# ESP32 register map
Vendor: ESPRESSIF SYSTEMS (SHANGHAI) CO., LTD.; Series: ESP32 Series; File version: 17
CPU: Xtensa LX6 r0p0, little endian, no MPU, FPU, 0 interrupt priority bits
Address unit: 32 bits
Registers are 32-bit, read-write, reset 0x0 unless marked. A register's access mark holds for its fields unless they carry their own. Offsets are from the block's base; [hi:lo] are bit positions; {n}, {i} and the like mark numbered series.

## SLC — SLC Peripheral
Base 0x3FF58000
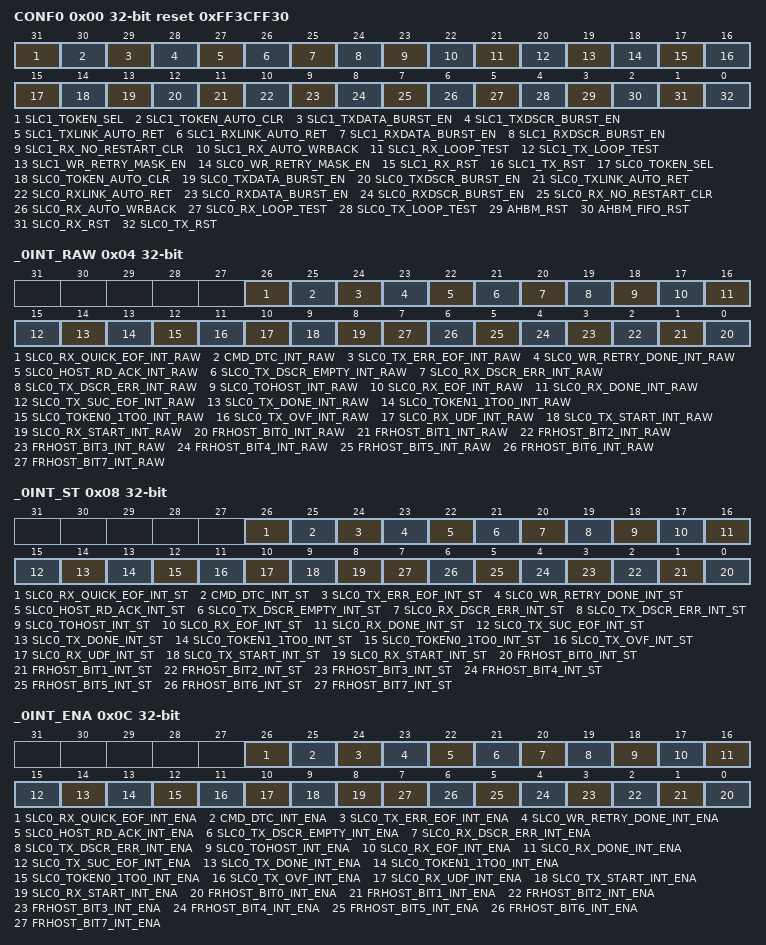
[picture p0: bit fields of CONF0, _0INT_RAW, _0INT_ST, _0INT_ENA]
0x00 CONF0 reset 0xFF3CFF30
  [31] SLC1_TOKEN_SEL, [30] SLC1_TOKEN_AUTO_CLR, [29] SLC1_TXDATA_BURST_EN, [28] SLC1_TXDSCR_BURST_EN, [27] SLC1_TXLINK_AUTO_RET, [26] SLC1_RXLINK_AUTO_RET, [25] SLC1_RXDATA_BURST_EN, [24] SLC1_RXDSCR_BURST_EN, [23] SLC1_RX_NO_RESTART_CLR, [22] SLC1_RX_AUTO_WRBACK, [21] SLC1_RX_LOOP_TEST, [20] SLC1_TX_LOOP_TEST, [19] SLC1_WR_RETRY_MASK_EN, [18] SLC0_WR_RETRY_MASK_EN, [17] SLC1_RX_RST, [16] SLC1_TX_RST, [15] SLC0_TOKEN_SEL, [14] SLC0_TOKEN_AUTO_CLR, [13] SLC0_TXDATA_BURST_EN, [12] SLC0_TXDSCR_BURST_EN, [11] SLC0_TXLINK_AUTO_RET, [10] SLC0_RXLINK_AUTO_RET, [9] SLC0_RXDATA_BURST_EN, [8] SLC0_RXDSCR_BURST_EN, [7] SLC0_RX_NO_RESTART_CLR, [6] SLC0_RX_AUTO_WRBACK, [5] SLC0_RX_LOOP_TEST, [4] SLC0_TX_LOOP_TEST, [3] AHBM_RST, [2] AHBM_FIFO_RST, [1] SLC0_RX_RST, [0] SLC0_TX_RST
0x04 _0INT_RAW ro
  [26] SLC0_RX_QUICK_EOF_INT_RAW, [25] CMD_DTC_INT_RAW, [24] SLC0_TX_ERR_EOF_INT_RAW, [23] SLC0_WR_RETRY_DONE_INT_RAW, [22] SLC0_HOST_RD_ACK_INT_RAW, [21] SLC0_TX_DSCR_EMPTY_INT_RAW, [20] SLC0_RX_DSCR_ERR_INT_RAW, [19] SLC0_TX_DSCR_ERR_INT_RAW, [18] SLC0_TOHOST_INT_RAW, [17] SLC0_RX_EOF_INT_RAW, [16] SLC0_RX_DONE_INT_RAW, [15] SLC0_TX_SUC_EOF_INT_RAW, [14] SLC0_TX_DONE_INT_RAW, [13] SLC0_TOKEN1_1TO0_INT_RAW, [12] SLC0_TOKEN0_1TO0_INT_RAW, [11] SLC0_TX_OVF_INT_RAW, [10] SLC0_RX_UDF_INT_RAW, [9] SLC0_TX_START_INT_RAW, [8] SLC0_RX_START_INT_RAW, [n] FRHOST_BIT{n}_INT_RAW (n=0..7)
0x08 _0INT_ST ro
  [26] SLC0_RX_QUICK_EOF_INT_ST, [25] CMD_DTC_INT_ST, [24] SLC0_TX_ERR_EOF_INT_ST, [23] SLC0_WR_RETRY_DONE_INT_ST, [22] SLC0_HOST_RD_ACK_INT_ST, [21] SLC0_TX_DSCR_EMPTY_INT_ST, [20] SLC0_RX_DSCR_ERR_INT_ST, [19] SLC0_TX_DSCR_ERR_INT_ST, [18] SLC0_TOHOST_INT_ST, [17] SLC0_RX_EOF_INT_ST, [16] SLC0_RX_DONE_INT_ST, [15] SLC0_TX_SUC_EOF_INT_ST, [14] SLC0_TX_DONE_INT_ST, [13] SLC0_TOKEN1_1TO0_INT_ST, [12] SLC0_TOKEN0_1TO0_INT_ST, [11] SLC0_TX_OVF_INT_ST, [10] SLC0_RX_UDF_INT_ST, [9] SLC0_TX_START_INT_ST, [8] SLC0_RX_START_INT_ST, [n] FRHOST_BIT{n}_INT_ST (n=0..7)
0x0C _0INT_ENA
  [26] SLC0_RX_QUICK_EOF_INT_ENA, [25] CMD_DTC_INT_ENA, [24] SLC0_TX_ERR_EOF_INT_ENA, [23] SLC0_WR_RETRY_DONE_INT_ENA, [22] SLC0_HOST_RD_ACK_INT_ENA, [21] SLC0_TX_DSCR_EMPTY_INT_ENA, [20] SLC0_RX_DSCR_ERR_INT_ENA, [19] SLC0_TX_DSCR_ERR_INT_ENA, [18] SLC0_TOHOST_INT_ENA, [17] SLC0_RX_EOF_INT_ENA, [16] SLC0_RX_DONE_INT_ENA, [15] SLC0_TX_SUC_EOF_INT_ENA, [14] SLC0_TX_DONE_INT_ENA, [13] SLC0_TOKEN1_1TO0_INT_ENA, [12] SLC0_TOKEN0_1TO0_INT_ENA, [11] SLC0_TX_OVF_INT_ENA, [10] SLC0_RX_UDF_INT_ENA, [9] SLC0_TX_START_INT_ENA, [8] SLC0_RX_START_INT_ENA, [n] FRHOST_BIT{n}_INT_ENA (n=0..7)
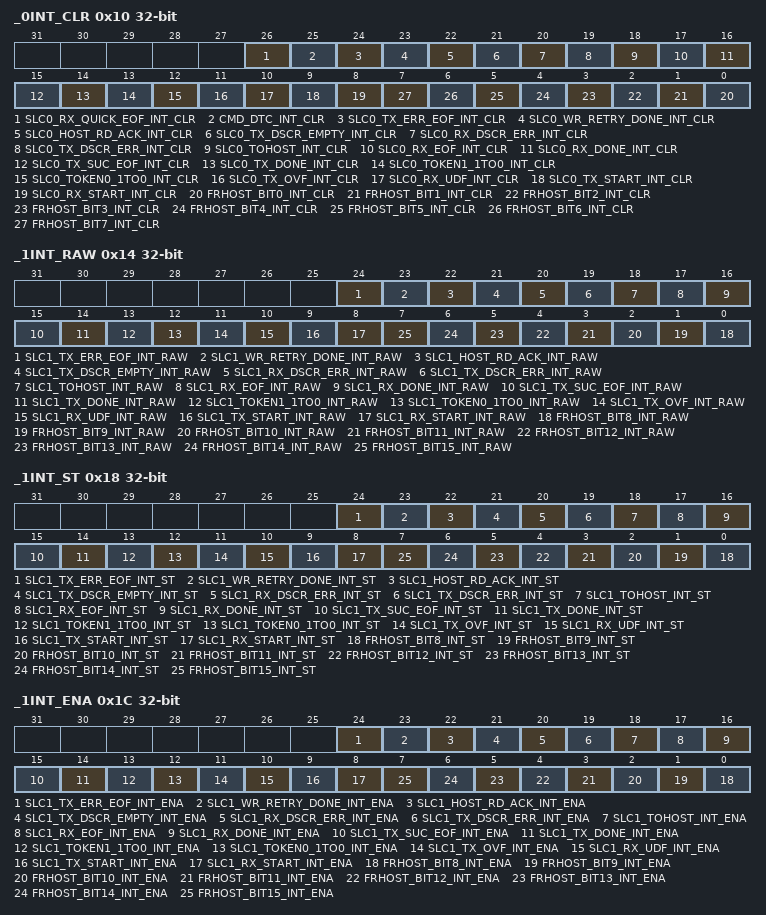
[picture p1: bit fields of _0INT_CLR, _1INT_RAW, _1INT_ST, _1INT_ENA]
0x10 _0INT_CLR wo
  [26] SLC0_RX_QUICK_EOF_INT_CLR, [25] CMD_DTC_INT_CLR, [24] SLC0_TX_ERR_EOF_INT_CLR, [23] SLC0_WR_RETRY_DONE_INT_CLR, [22] SLC0_HOST_RD_ACK_INT_CLR, [21] SLC0_TX_DSCR_EMPTY_INT_CLR, [20] SLC0_RX_DSCR_ERR_INT_CLR, [19] SLC0_TX_DSCR_ERR_INT_CLR, [18] SLC0_TOHOST_INT_CLR, [17] SLC0_RX_EOF_INT_CLR, [16] SLC0_RX_DONE_INT_CLR, [15] SLC0_TX_SUC_EOF_INT_CLR, [14] SLC0_TX_DONE_INT_CLR, [13] SLC0_TOKEN1_1TO0_INT_CLR, [12] SLC0_TOKEN0_1TO0_INT_CLR, [11] SLC0_TX_OVF_INT_CLR, [10] SLC0_RX_UDF_INT_CLR, [9] SLC0_TX_START_INT_CLR, [8] SLC0_RX_START_INT_CLR, [n] FRHOST_BIT{n}_INT_CLR (n=0..7)
0x14 _1INT_RAW ro
  [24] SLC1_TX_ERR_EOF_INT_RAW, [23] SLC1_WR_RETRY_DONE_INT_RAW, [22] SLC1_HOST_RD_ACK_INT_RAW, [21] SLC1_TX_DSCR_EMPTY_INT_RAW, [20] SLC1_RX_DSCR_ERR_INT_RAW, [19] SLC1_TX_DSCR_ERR_INT_RAW, [18] SLC1_TOHOST_INT_RAW, [17] SLC1_RX_EOF_INT_RAW, [16] SLC1_RX_DONE_INT_RAW, [15] SLC1_TX_SUC_EOF_INT_RAW, [14] SLC1_TX_DONE_INT_RAW, [13] SLC1_TOKEN1_1TO0_INT_RAW, [12] SLC1_TOKEN0_1TO0_INT_RAW, [11] SLC1_TX_OVF_INT_RAW, [10] SLC1_RX_UDF_INT_RAW, [9] SLC1_TX_START_INT_RAW, [8] SLC1_RX_START_INT_RAW, [n-8] FRHOST_BIT{n}_INT_RAW (n=8..15)
0x18 _1INT_ST ro
  [24] SLC1_TX_ERR_EOF_INT_ST, [23] SLC1_WR_RETRY_DONE_INT_ST, [22] SLC1_HOST_RD_ACK_INT_ST, [21] SLC1_TX_DSCR_EMPTY_INT_ST, [20] SLC1_RX_DSCR_ERR_INT_ST, [19] SLC1_TX_DSCR_ERR_INT_ST, [18] SLC1_TOHOST_INT_ST, [17] SLC1_RX_EOF_INT_ST, [16] SLC1_RX_DONE_INT_ST, [15] SLC1_TX_SUC_EOF_INT_ST, [14] SLC1_TX_DONE_INT_ST, [13] SLC1_TOKEN1_1TO0_INT_ST, [12] SLC1_TOKEN0_1TO0_INT_ST, [11] SLC1_TX_OVF_INT_ST, [10] SLC1_RX_UDF_INT_ST, [9] SLC1_TX_START_INT_ST, [8] SLC1_RX_START_INT_ST, [n-8] FRHOST_BIT{n}_INT_ST (n=8..15)
0x1C _1INT_ENA
  [24] SLC1_TX_ERR_EOF_INT_ENA, [23] SLC1_WR_RETRY_DONE_INT_ENA, [22] SLC1_HOST_RD_ACK_INT_ENA, [21] SLC1_TX_DSCR_EMPTY_INT_ENA, [20] SLC1_RX_DSCR_ERR_INT_ENA, [19] SLC1_TX_DSCR_ERR_INT_ENA, [18] SLC1_TOHOST_INT_ENA, [17] SLC1_RX_EOF_INT_ENA, [16] SLC1_RX_DONE_INT_ENA, [15] SLC1_TX_SUC_EOF_INT_ENA, [14] SLC1_TX_DONE_INT_ENA, [13] SLC1_TOKEN1_1TO0_INT_ENA, [12] SLC1_TOKEN0_1TO0_INT_ENA, [11] SLC1_TX_OVF_INT_ENA, [10] SLC1_RX_UDF_INT_ENA, [9] SLC1_TX_START_INT_ENA, [8] SLC1_RX_START_INT_ENA, [n-8] FRHOST_BIT{n}_INT_ENA (n=8..15)
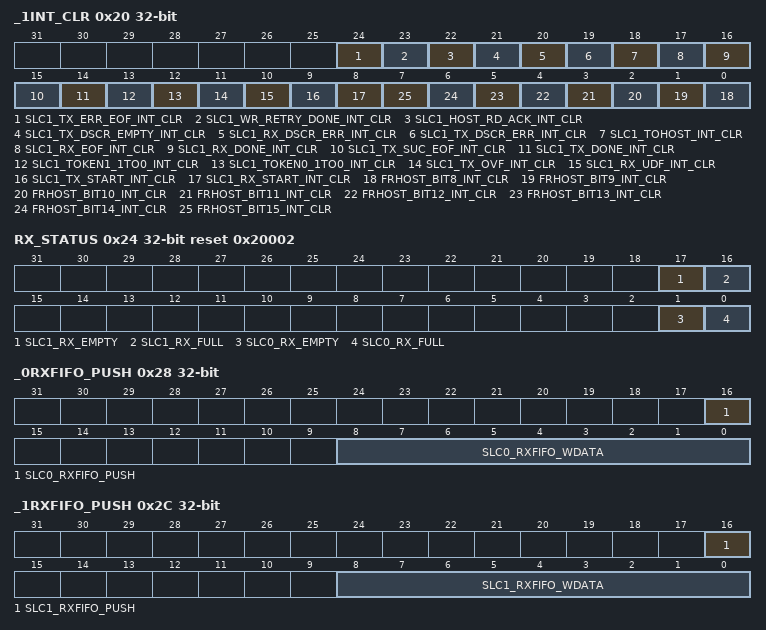
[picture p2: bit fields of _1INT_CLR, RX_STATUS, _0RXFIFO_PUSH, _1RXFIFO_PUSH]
0x20 _1INT_CLR wo
  [24] SLC1_TX_ERR_EOF_INT_CLR, [23] SLC1_WR_RETRY_DONE_INT_CLR, [22] SLC1_HOST_RD_ACK_INT_CLR, [21] SLC1_TX_DSCR_EMPTY_INT_CLR, [20] SLC1_RX_DSCR_ERR_INT_CLR, [19] SLC1_TX_DSCR_ERR_INT_CLR, [18] SLC1_TOHOST_INT_CLR, [17] SLC1_RX_EOF_INT_CLR, [16] SLC1_RX_DONE_INT_CLR, [15] SLC1_TX_SUC_EOF_INT_CLR, [14] SLC1_TX_DONE_INT_CLR, [13] SLC1_TOKEN1_1TO0_INT_CLR, [12] SLC1_TOKEN0_1TO0_INT_CLR, [11] SLC1_TX_OVF_INT_CLR, [10] SLC1_RX_UDF_INT_CLR, [9] SLC1_TX_START_INT_CLR, [8] SLC1_RX_START_INT_CLR, [n-8] FRHOST_BIT{n}_INT_CLR (n=8..15)
0x24 RX_STATUS ro reset 0x20002
  [17] SLC1_RX_EMPTY, [16] SLC1_RX_FULL, [1] SLC0_RX_EMPTY, [0] SLC0_RX_FULL
0x28 _0RXFIFO_PUSH
  [16] SLC0_RXFIFO_PUSH, [8:0] SLC0_RXFIFO_WDATA
0x2C _1RXFIFO_PUSH
  [16] SLC1_RXFIFO_PUSH, [8:0] SLC1_RXFIFO_WDATA
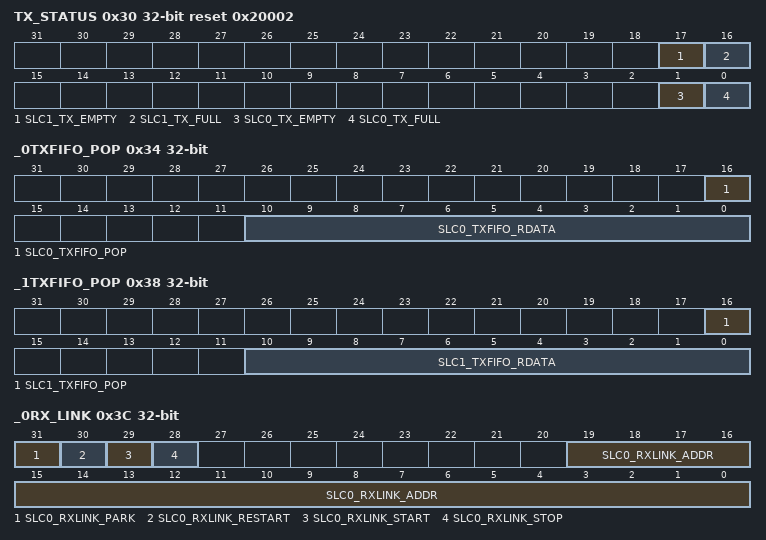
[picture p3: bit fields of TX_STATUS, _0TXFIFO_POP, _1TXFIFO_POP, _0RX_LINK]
0x30 TX_STATUS ro reset 0x20002
  [17] SLC1_TX_EMPTY, [16] SLC1_TX_FULL, [1] SLC0_TX_EMPTY, [0] SLC0_TX_FULL
0x34 _0TXFIFO_POP access per field
  [16] SLC0_TXFIFO_POP rw, [10:0] SLC0_TXFIFO_RDATA ro
0x38 _1TXFIFO_POP access per field
  [16] SLC1_TXFIFO_POP rw, [10:0] SLC1_TXFIFO_RDATA ro
0x3C _0RX_LINK access per field
  [31] SLC0_RXLINK_PARK ro, [30] SLC0_RXLINK_RESTART rw, [29] SLC0_RXLINK_START rw, [28] SLC0_RXLINK_STOP rw, [19:0] SLC0_RXLINK_ADDR rw
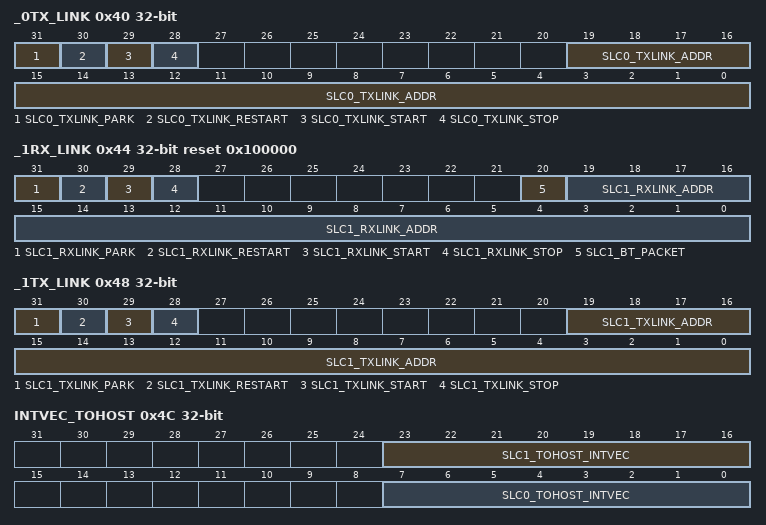
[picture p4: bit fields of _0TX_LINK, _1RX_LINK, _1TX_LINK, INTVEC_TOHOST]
0x40 _0TX_LINK access per field
  [31] SLC0_TXLINK_PARK ro, [30] SLC0_TXLINK_RESTART rw, [29] SLC0_TXLINK_START rw, [28] SLC0_TXLINK_STOP rw, [19:0] SLC0_TXLINK_ADDR rw
0x44 _1RX_LINK access per field reset 0x100000
  [31] SLC1_RXLINK_PARK ro, [30] SLC1_RXLINK_RESTART rw, [29] SLC1_RXLINK_START rw, [28] SLC1_RXLINK_STOP rw, [20] SLC1_BT_PACKET rw, [19:0] SLC1_RXLINK_ADDR rw
0x48 _1TX_LINK access per field
  [31] SLC1_TXLINK_PARK ro, [30] SLC1_TXLINK_RESTART rw, [29] SLC1_TXLINK_START rw, [28] SLC1_TXLINK_STOP rw, [19:0] SLC1_TXLINK_ADDR rw
0x4C INTVEC_TOHOST wo
  [23:16] SLC1_TOHOST_INTVEC, [7:0] SLC0_TOHOST_INTVEC
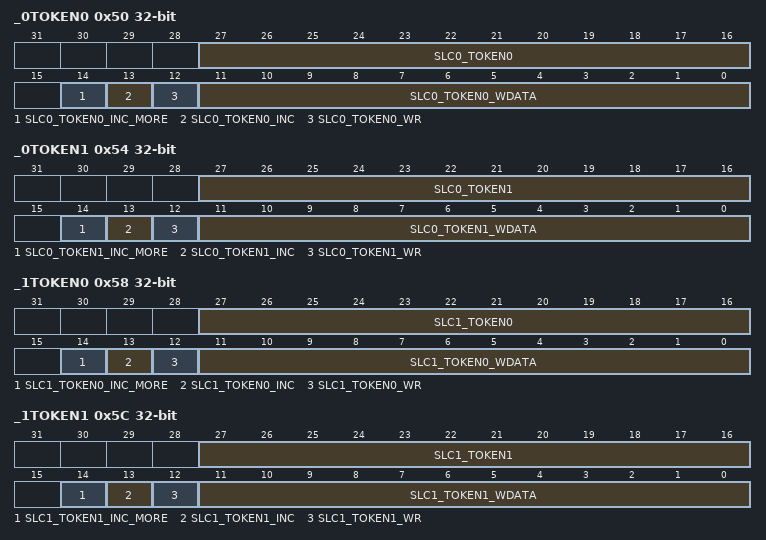
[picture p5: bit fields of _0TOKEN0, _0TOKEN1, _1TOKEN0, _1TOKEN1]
0x50 _0TOKEN0 access per field
  [27:16] SLC0_TOKEN0 ro, [14] SLC0_TOKEN0_INC_MORE wo, [13] SLC0_TOKEN0_INC wo, [12] SLC0_TOKEN0_WR wo, [11:0] SLC0_TOKEN0_WDATA wo
0x54 _0TOKEN1 access per field
  [27:16] SLC0_TOKEN1 ro, [14] SLC0_TOKEN1_INC_MORE wo, [13] SLC0_TOKEN1_INC wo, [12] SLC0_TOKEN1_WR wo, [11:0] SLC0_TOKEN1_WDATA wo
0x58 _1TOKEN0 access per field
  [27:16] SLC1_TOKEN0 ro, [14] SLC1_TOKEN0_INC_MORE wo, [13] SLC1_TOKEN0_INC wo, [12] SLC1_TOKEN0_WR wo, [11:0] SLC1_TOKEN0_WDATA wo
0x5C _1TOKEN1 access per field
  [27:16] SLC1_TOKEN1 ro, [14] SLC1_TOKEN1_INC_MORE wo, [13] SLC1_TOKEN1_INC wo, [12] SLC1_TOKEN1_WR wo, [11:0] SLC1_TOKEN1_WDATA wo
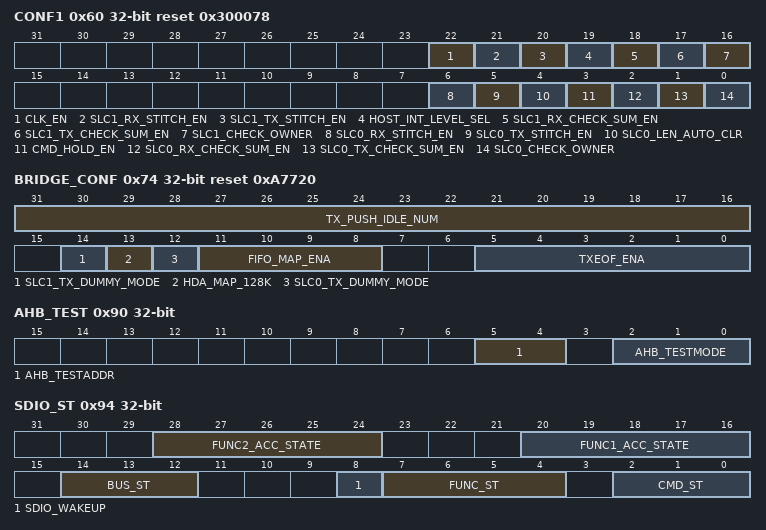
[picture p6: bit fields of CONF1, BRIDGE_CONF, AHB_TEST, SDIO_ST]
0x60 CONF1 reset 0x300078
  [22] CLK_EN, [21] SLC1_RX_STITCH_EN, [20] SLC1_TX_STITCH_EN, [19] HOST_INT_LEVEL_SEL, [18] SLC1_RX_CHECK_SUM_EN, [17] SLC1_TX_CHECK_SUM_EN, [16] SLC1_CHECK_OWNER, [6] SLC0_RX_STITCH_EN, [5] SLC0_TX_STITCH_EN, [4] SLC0_LEN_AUTO_CLR, [3] CMD_HOLD_EN, [2] SLC0_RX_CHECK_SUM_EN, [1] SLC0_TX_CHECK_SUM_EN, [0] SLC0_CHECK_OWNER
0x64 _0_STATE0 ro
  [31:0] SLC0_STATE0
0x68 _0_STATE1 ro
  [31:0] SLC0_STATE1
0x6C _1_STATE0 ro
  [31:0] SLC1_STATE0
0x70 _1_STATE1 ro
  [31:0] SLC1_STATE1
0x74 BRIDGE_CONF reset 0xA7720
  [31:16] TX_PUSH_IDLE_NUM, [14] SLC1_TX_DUMMY_MODE, [13] HDA_MAP_128K, [12] SLC0_TX_DUMMY_MODE, [11:8] FIFO_MAP_ENA, [5:0] TXEOF_ENA
0x78 _0_TO_EOF_DES_ADDR ro
  [31:0] SLC0_TO_EOF_DES_ADDR
0x7C _0_TX_EOF_DES_ADDR ro
  [31:0] SLC0_TX_SUC_EOF_DES_ADDR
0x80 _0_TO_EOF_BFR_DES_ADDR ro
  [31:0] SLC0_TO_EOF_BFR_DES_ADDR
0x84 _1_TO_EOF_DES_ADDR ro
  [31:0] SLC1_TO_EOF_DES_ADDR
0x88 _1_TX_EOF_DES_ADDR ro
  [31:0] SLC1_TX_SUC_EOF_DES_ADDR
0x8C _1_TO_EOF_BFR_DES_ADDR ro
  [31:0] SLC1_TO_EOF_BFR_DES_ADDR
0x90 AHB_TEST
  [5:4] AHB_TESTADDR, [2:0] AHB_TESTMODE
0x94 SDIO_ST ro
  [28:24] FUNC2_ACC_STATE, [20:16] FUNC1_ACC_STATE, [14:12] BUS_ST, [8] SDIO_WAKEUP, [7:4] FUNC_ST, [2:0] CMD_ST
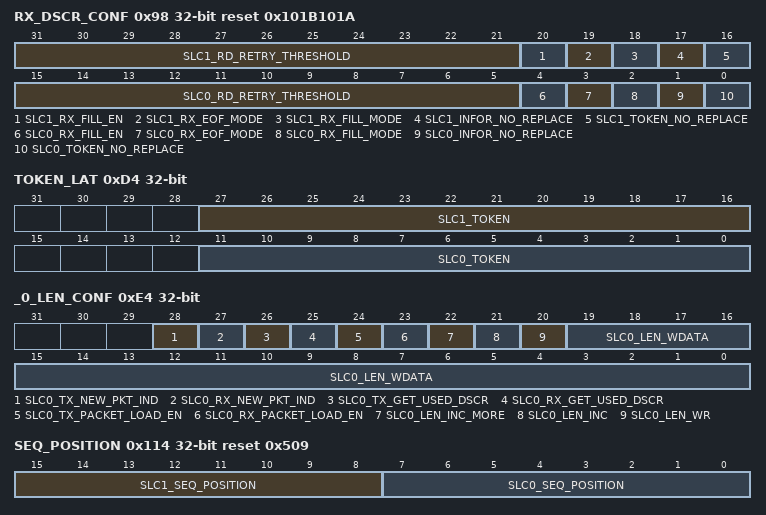
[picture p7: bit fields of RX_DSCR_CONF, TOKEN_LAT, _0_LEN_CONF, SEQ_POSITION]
0x98 RX_DSCR_CONF reset 0x101B101A
  [31:21] SLC1_RD_RETRY_THRESHOLD, [20] SLC1_RX_FILL_EN, [19] SLC1_RX_EOF_MODE, [18] SLC1_RX_FILL_MODE, [17] SLC1_INFOR_NO_REPLACE, [16] SLC1_TOKEN_NO_REPLACE, [15:5] SLC0_RD_RETRY_THRESHOLD, [4] SLC0_RX_FILL_EN, [3] SLC0_RX_EOF_MODE, [2] SLC0_RX_FILL_MODE, [1] SLC0_INFOR_NO_REPLACE, [0] SLC0_TOKEN_NO_REPLACE
0x9C _0_TXLINK_DSCR ro
  [31:0] SLC0_TXLINK_DSCR
0xA0 _0_TXLINK_DSCR_BF0 ro
  [31:0] SLC0_TXLINK_DSCR_BF0
0xA4 _0_TXLINK_DSCR_BF1 ro
  [31:0] SLC0_TXLINK_DSCR_BF1
0xA8 _0_RXLINK_DSCR ro
  [31:0] SLC0_RXLINK_DSCR
0xAC _0_RXLINK_DSCR_BF0 ro
  [31:0] SLC0_RXLINK_DSCR_BF0
0xB0 _0_RXLINK_DSCR_BF1 ro
  [31:0] SLC0_RXLINK_DSCR_BF1
0xB4 _1_TXLINK_DSCR ro
  [31:0] SLC1_TXLINK_DSCR
0xB8 _1_TXLINK_DSCR_BF0 ro
  [31:0] SLC1_TXLINK_DSCR_BF0
0xBC _1_TXLINK_DSCR_BF1 ro
  [31:0] SLC1_TXLINK_DSCR_BF1
0xC0 _1_RXLINK_DSCR ro
  [31:0] SLC1_RXLINK_DSCR
0xC4 _1_RXLINK_DSCR_BF0 ro
  [31:0] SLC1_RXLINK_DSCR_BF0
0xC8 _1_RXLINK_DSCR_BF1 ro
  [31:0] SLC1_RXLINK_DSCR_BF1
0xCC _0_TX_ERREOF_DES_ADDR ro
  [31:0] SLC0_TX_ERR_EOF_DES_ADDR
0xD0 _1_TX_ERREOF_DES_ADDR ro
  [31:0] SLC1_TX_ERR_EOF_DES_ADDR
0xD4 TOKEN_LAT ro
  [27:16] SLC1_TOKEN, [11:0] SLC0_TOKEN
0xD8 TX_DSCR_CONF reset 0x80
  [10:0] WR_RETRY_THRESHOLD
0xDC CMD_INFOR0 ro
  [31:0] CMD_CONTENT0
0xE0 CMD_INFOR1 ro
  [31:0] CMD_CONTENT1
0xE4 _0_LEN_CONF access per field
  [28] SLC0_TX_NEW_PKT_IND ro, [27] SLC0_RX_NEW_PKT_IND ro, [26] SLC0_TX_GET_USED_DSCR wo, [25] SLC0_RX_GET_USED_DSCR wo, [24] SLC0_TX_PACKET_LOAD_EN rw, [23] SLC0_RX_PACKET_LOAD_EN rw, [22] SLC0_LEN_INC_MORE wo, [21] SLC0_LEN_INC wo, [20] SLC0_LEN_WR wo, [19:0] SLC0_LEN_WDATA wo
0xE8 _0_LENGTH ro
  [19:0] SLC0_LEN
0xEC _0_TXPKT_H_DSCR
  [31:0] SLC0_TX_PKT_H_DSCR_ADDR
0xF0 _0_TXPKT_E_DSCR
  [31:0] SLC0_TX_PKT_E_DSCR_ADDR
0xF4 _0_RXPKT_H_DSCR
  [31:0] SLC0_RX_PKT_H_DSCR_ADDR
0xF8 _0_RXPKT_E_DSCR
  [31:0] SLC0_RX_PKT_E_DSCR_ADDR
0xFC _0_TXPKTU_H_DSCR ro
  [31:0] SLC0_TX_PKT_START_DSCR_ADDR
0x100 _0_TXPKTU_E_DSCR ro
  [31:0] SLC0_TX_PKT_END_DSCR_ADDR
0x104 _0_RXPKTU_H_DSCR ro
  [31:0] SLC0_RX_PKT_START_DSCR_ADDR
0x108 _0_RXPKTU_E_DSCR ro
  [31:0] SLC0_RX_PKT_END_DSCR_ADDR
0x114 SEQ_POSITION reset 0x509
  [15:8] SLC1_SEQ_POSITION, [7:0] SLC0_SEQ_POSITION
0x118 _0_DSCR_REC_CONF reset 0x3FF
  [9:0] SLC0_RX_DSCR_REC_LIM
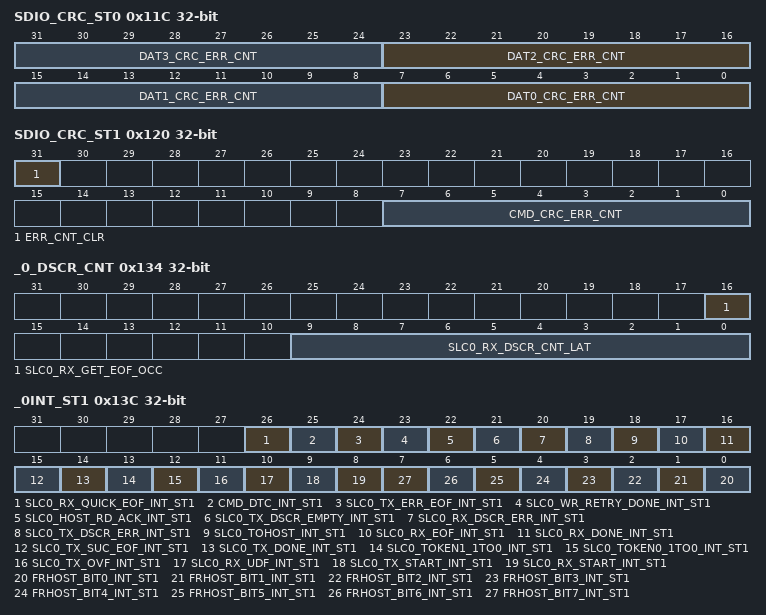
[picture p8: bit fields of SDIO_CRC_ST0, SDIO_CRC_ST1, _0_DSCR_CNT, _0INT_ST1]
0x11C SDIO_CRC_ST0 ro
  [8n+7:8n] DAT{n}_CRC_ERR_CNT (n=0..3)
0x120 SDIO_CRC_ST1 access per field
  [31] ERR_CNT_CLR rw, [7:0] CMD_CRC_ERR_CNT ro
0x124 _0_EOF_START_DES ro
  [31:0] SLC0_EOF_START_DES_ADDR
0x128 _0_PUSH_DSCR_ADDR ro
  [31:0] SLC0_RX_PUSH_DSCR_ADDR
0x12C _0_DONE_DSCR_ADDR ro
  [31:0] SLC0_RX_DONE_DSCR_ADDR
0x130 _0_SUB_START_DES ro
  [31:0] SLC0_SUB_PAC_START_DSCR_ADDR
0x134 _0_DSCR_CNT ro
  [16] SLC0_RX_GET_EOF_OCC, [9:0] SLC0_RX_DSCR_CNT_LAT
0x138 _0_LEN_LIM_CONF reset 0x5400
  [19:0] SLC0_LEN_LIM
0x13C _0INT_ST1 ro
  [26] SLC0_RX_QUICK_EOF_INT_ST1, [25] CMD_DTC_INT_ST1, [24] SLC0_TX_ERR_EOF_INT_ST1, [23] SLC0_WR_RETRY_DONE_INT_ST1, [22] SLC0_HOST_RD_ACK_INT_ST1, [21] SLC0_TX_DSCR_EMPTY_INT_ST1, [20] SLC0_RX_DSCR_ERR_INT_ST1, [19] SLC0_TX_DSCR_ERR_INT_ST1, [18] SLC0_TOHOST_INT_ST1, [17] SLC0_RX_EOF_INT_ST1, [16] SLC0_RX_DONE_INT_ST1, [15] SLC0_TX_SUC_EOF_INT_ST1, [14] SLC0_TX_DONE_INT_ST1, [13] SLC0_TOKEN1_1TO0_INT_ST1, [12] SLC0_TOKEN0_1TO0_INT_ST1, [11] SLC0_TX_OVF_INT_ST1, [10] SLC0_RX_UDF_INT_ST1, [9] SLC0_TX_START_INT_ST1, [8] SLC0_RX_START_INT_ST1, [n] FRHOST_BIT{n}_INT_ST1 (n=0..7)
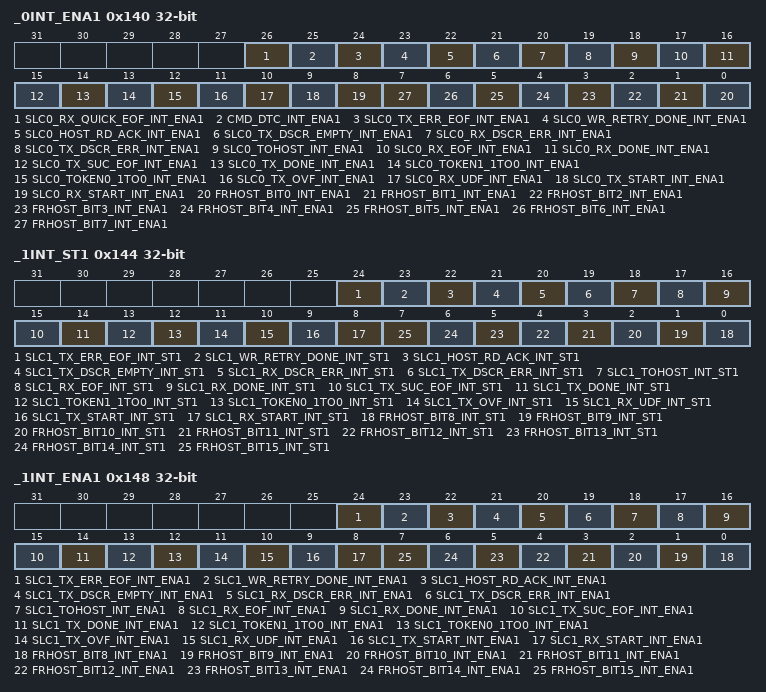
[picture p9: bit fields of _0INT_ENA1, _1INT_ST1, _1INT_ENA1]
0x140 _0INT_ENA1
  [26] SLC0_RX_QUICK_EOF_INT_ENA1, [25] CMD_DTC_INT_ENA1, [24] SLC0_TX_ERR_EOF_INT_ENA1, [23] SLC0_WR_RETRY_DONE_INT_ENA1, [22] SLC0_HOST_RD_ACK_INT_ENA1, [21] SLC0_TX_DSCR_EMPTY_INT_ENA1, [20] SLC0_RX_DSCR_ERR_INT_ENA1, [19] SLC0_TX_DSCR_ERR_INT_ENA1, [18] SLC0_TOHOST_INT_ENA1, [17] SLC0_RX_EOF_INT_ENA1, [16] SLC0_RX_DONE_INT_ENA1, [15] SLC0_TX_SUC_EOF_INT_ENA1, [14] SLC0_TX_DONE_INT_ENA1, [13] SLC0_TOKEN1_1TO0_INT_ENA1, [12] SLC0_TOKEN0_1TO0_INT_ENA1, [11] SLC0_TX_OVF_INT_ENA1, [10] SLC0_RX_UDF_INT_ENA1, [9] SLC0_TX_START_INT_ENA1, [8] SLC0_RX_START_INT_ENA1, [n] FRHOST_BIT{n}_INT_ENA1 (n=0..7)
0x144 _1INT_ST1 ro
  [24] SLC1_TX_ERR_EOF_INT_ST1, [23] SLC1_WR_RETRY_DONE_INT_ST1, [22] SLC1_HOST_RD_ACK_INT_ST1, [21] SLC1_TX_DSCR_EMPTY_INT_ST1, [20] SLC1_RX_DSCR_ERR_INT_ST1, [19] SLC1_TX_DSCR_ERR_INT_ST1, [18] SLC1_TOHOST_INT_ST1, [17] SLC1_RX_EOF_INT_ST1, [16] SLC1_RX_DONE_INT_ST1, [15] SLC1_TX_SUC_EOF_INT_ST1, [14] SLC1_TX_DONE_INT_ST1, [13] SLC1_TOKEN1_1TO0_INT_ST1, [12] SLC1_TOKEN0_1TO0_INT_ST1, [11] SLC1_TX_OVF_INT_ST1, [10] SLC1_RX_UDF_INT_ST1, [9] SLC1_TX_START_INT_ST1, [8] SLC1_RX_START_INT_ST1, [n-8] FRHOST_BIT{n}_INT_ST1 (n=8..15)
0x148 _1INT_ENA1
  [24] SLC1_TX_ERR_EOF_INT_ENA1, [23] SLC1_WR_RETRY_DONE_INT_ENA1, [22] SLC1_HOST_RD_ACK_INT_ENA1, [21] SLC1_TX_DSCR_EMPTY_INT_ENA1, [20] SLC1_RX_DSCR_ERR_INT_ENA1, [19] SLC1_TX_DSCR_ERR_INT_ENA1, [18] SLC1_TOHOST_INT_ENA1, [17] SLC1_RX_EOF_INT_ENA1, [16] SLC1_RX_DONE_INT_ENA1, [15] SLC1_TX_SUC_EOF_INT_ENA1, [14] SLC1_TX_DONE_INT_ENA1, [13] SLC1_TOKEN1_1TO0_INT_ENA1, [12] SLC1_TOKEN0_1TO0_INT_ENA1, [11] SLC1_TX_OVF_INT_ENA1, [10] SLC1_RX_UDF_INT_ENA1, [9] SLC1_TX_START_INT_ENA1, [8] SLC1_RX_START_INT_ENA1, [n-8] FRHOST_BIT{n}_INT_ENA1 (n=8..15)
0x1F8 DATE reset 0x16022500
0x1FC ID reset 0x100
